# AE612FA0E5597BS0_CM55_HP_View register map
Vendor: Alif Semiconductor; Series: E6; File version: 1.0
CPU: CM55 r1p0, selectable endian, MPU, FPU, double-precision FPU, DSP, VTOR, 8 interrupt priority bits, 1 SAU regions
Registers are 32-bit, read-write, reset 0x0 unless marked. A register's access mark holds for its fields unless they carry their own. Offsets are from the block's base; [hi:lo] are bit positions; {n}, {i} and the like mark numbered series; 'fields as' and 'values as' point back to an identical list.

## NPU_HG
Base 0x49042000
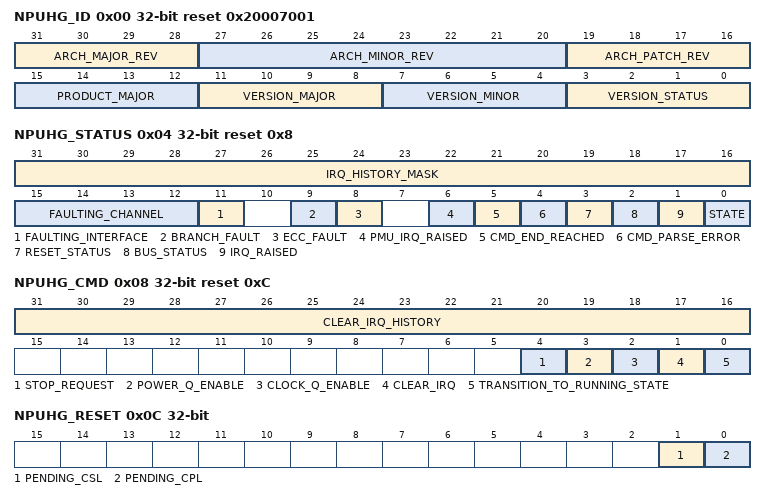
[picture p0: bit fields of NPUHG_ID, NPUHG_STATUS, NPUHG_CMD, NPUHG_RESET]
0x00 NPUHG_ID ro reset 0x20007001 — ID Register
  [31:28] ARCH_MAJOR_REV — This value is the major architecture version number, a in the architecture version a.b
  [27:20] ARCH_MINOR_REV — This value is the minor architecture version number, b in the architecture version a.b
  [19:16] ARCH_PATCH_REV — This value is the patch number of the architecture version a.b
  [15:12] PRODUCT_MAJOR — Product major ID number (unique per base product)
  [11:8] VERSION_MAJOR — This value is the n for the R part of an RnPn release number
  [7:4] VERSION_MINOR — This value is the n for the P part of an RnPn release number
  [3:0] VERSION_STATUS — This value is the version of the product
0x04 NPUHG_STATUS ro reset 0x8 — STATUS Register
  [31:16] IRQ_HISTORY_MASK — The IRQ History mask
  [15:12] FAULTING_CHANNEL — The faulting channel on a bus abort
  [11] FAULTING_INTERFACE — The faulting interface on bus abort
  [9] BRANCH_FAULT
    0=No branch fault; 1=Branch fault detected
  [8] ECC_FAULT
    0=No ECC fault detected; 1=ECC fault detected
  [6] PMU_IRQ_RAISED
    0=No PMU IRQ raised; 1=PMU IRQ raised
  [5] CMD_END_REACHED
    0=Command stream end is not reached; 1=Command stream end is reached
  [4] CMD_PARSE_ERROR
    0=No parsing error; 1=Command stream parsing error detected
  [3] RESET_STATUS
    0=No reset in progress; 1=Reset in progress
  [2] BUS_STATUS
    0=No bus fault; 1=Bus abort detected and processing halted
  [1] IRQ_RAISED
    0=IRQ not raised; 1=IRQ raised
  [0] STATE
    0=NPU is in stopped state; 1=NPU is in running state
0x08 NPUHG_CMD reset 0xC — CMD Register
  [31:16] CLEAR_IRQ_HISTORY — Clears the IRQ history mask
  [4] STOP_REQUEST — Write 1 to this bit to request STOP after completing any already-started commands
  [3] POWER_Q_ENABLE — Write 1 to this bit to enable power off using power q-interface
  [2] CLOCK_Q_ENABLE — Write 1 to this bit to enable clock off using clock q-interface and enable the requester clock gate
  [1] CLEAR_IRQ — Write 1 to clear the IRQ status in the NPUHG_STATUS register. Writing 0 has no effect.
  [0] TRANSITION_TO_RUNNING_STATE — Write 1 to transition the NPU to running state. Writing 0 has no effect.
0x0C NPUHG_RESET — RESET Register
  [1] PENDING_CSL — Current security level
    0=Secure; 1=Non-secure
  [0] PENDING_CPL — Current privilege level
    0=User; 1=Privileged
0x10 NPUHG_QBASE — QBASE Register
  [31:0] OFFSET
0x14 NPUHG_QBASE_HI — QBASE_HI Register
  [7:0] OFFSET
0x18 NPUHG_QREAD ro — QREAD Register
  [31:0] QREAD — The read offset of the current command under execution
0x1C NPUHG_QCONFIG — QCONFIG Register
  [1:0] CMD_REGION0 — The command region configuration number
0x20 NPUHG_QSIZE — QSIZE Register
  [31:0] QSIZE — The size of the next command stream to be executed by the NPU
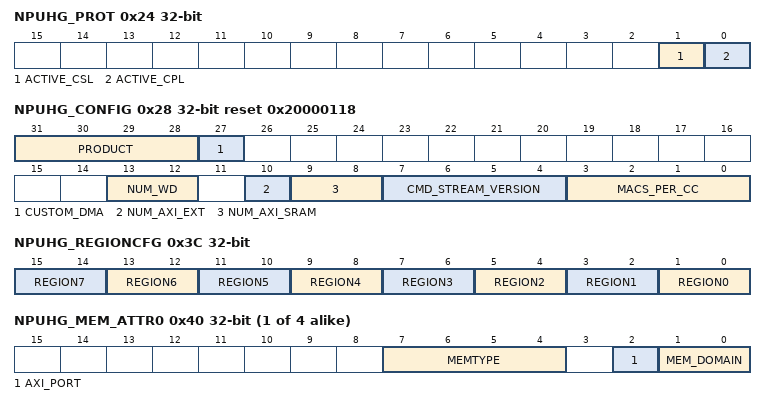
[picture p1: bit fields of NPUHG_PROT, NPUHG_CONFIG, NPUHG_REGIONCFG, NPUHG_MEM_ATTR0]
0x24 NPUHG_PROT ro — PROT Register
  [1] ACTIVE_CSL — The current security level
    0=Secure; 1=Non secure
  [0] ACTIVE_CPL — The current privilege level
    0=User; 1=Privileged
0x28 NPUHG_CONFIG ro reset 0x20000118 — CONFIG Register
  [31:28] PRODUCT — The product configuration
  [27] CUSTOM_DMA — The custom DMA configuration
  [13:12] NUM_WD — The log2 of the number of standard weight decoders
  [10] NUM_AXI_EXT — The log2 of the number of AXI External memory interfaces
  [9:8] NUM_AXI_SRAM — The log2 of the number of AXI SRAM interfaces
  [7:4] CMD_STREAM_VERSION — The command stream version accepted by this NPU
  [3:0] MACS_PER_CC — The log2(MACs/clock cycle)
0x30 NPUHG_COND_STATUS ro — COND_STATUS Register
  [0] RESULT_FLAG — The tensor result flag. For OFM with a single element, this is bit 0 of the value. Otherwise unpredictable.
0x38 NPUHG_POWER_CTRL — POWER_CTRL Register
  [5:0] MAC_STEP_CYCLES — MAC power ramping up/down control
0x3C NPUHG_REGIONCFG — REGIONCFG Register
  [2n+1:2n] REGION{n} (n=0..7) — Bits for Region{n} Configuration
{0x40+4i} NPUHG_MEM_ATTR{i} (i=0..3) — MEM_ATTR{i} Register
  [7:4] MEMTYPE — Memtype to be used to encode AxCACHE signals
  [2] AXI_PORT — AXI port select
  [1:0] MEM_DOMAIN — Memory domain
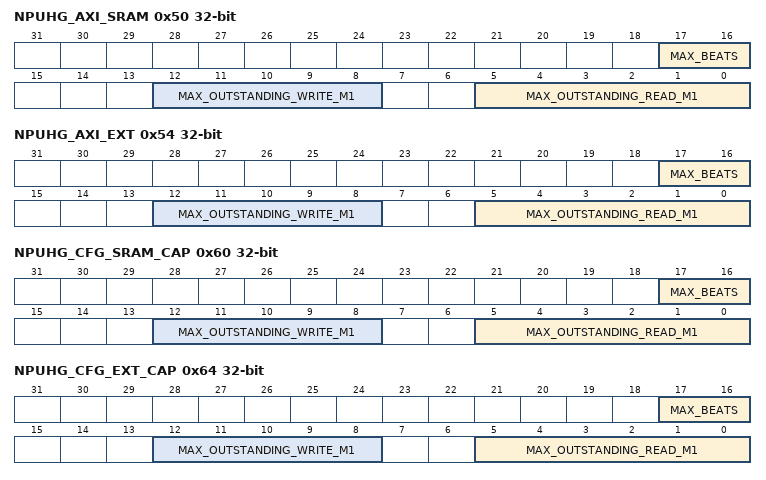
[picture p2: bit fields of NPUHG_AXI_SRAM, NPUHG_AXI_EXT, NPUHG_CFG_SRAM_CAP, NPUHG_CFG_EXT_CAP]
0x50 NPUHG_AXI_SRAM — AXI_SRAM Register
  [17:16] MAX_BEATS — Burst split alignment
  [12:8] MAX_OUTSTANDING_WRITE_M1 — Maximum number of outstanding AXI write transactions per port - 1
  [5:0] MAX_OUTSTANDING_READ_M1 — Maximum number of outstanding AXI read transactions per port - 1
0x54 NPUHG_AXI_EXT — AXI_EXT Register
  fields as NPUHG_AXI_SRAM
0x60 NPUHG_CFG_SRAM_CAP ro — CFG_SRAM_CAP Register
  fields as NPUHG_AXI_SRAM
0x64 NPUHG_CFG_EXT_CAP ro — CFG_EXT_CAP Register
  fields as NPUHG_AXI_SRAM
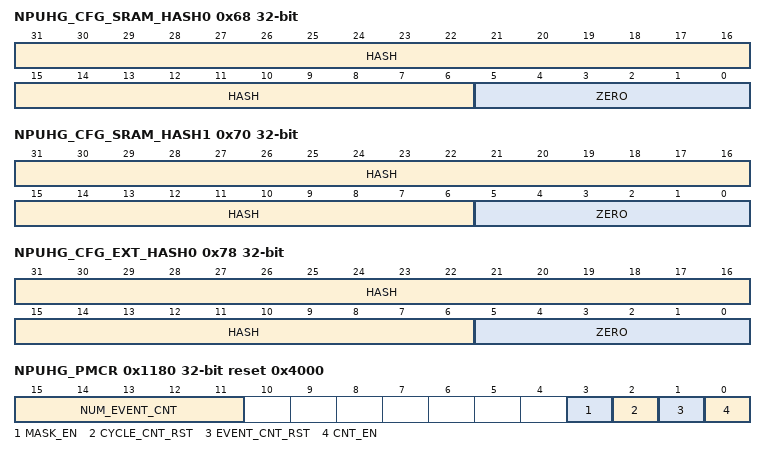
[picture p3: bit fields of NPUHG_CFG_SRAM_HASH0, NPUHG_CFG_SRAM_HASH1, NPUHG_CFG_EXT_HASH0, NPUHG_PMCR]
0x68 NPUHG_CFG_SRAM_HASH0 ro — CFG_SRAM_HASH0 Register
  [31:6] HASH — Hash function
  [5:0] ZERO — Must be zero
0x6C NPUHG_CFG_SRAM_HASH0_HI ro — CFG_SRAM_HASH0_HI Register
  [7:0] HASH — Hash function
0x70 NPUHG_CFG_SRAM_HASH1 ro — CFG_SRAM_HASH1 Register
  [31:6] HASH — Hash function
  [5:0] ZERO — Must be zero
0x74 NPUHG_CFG_SRAM_HASH1_HI ro — CFG_SRAM_HASH1_HI Register
  [7:0] HASH — Hash function
0x78 NPUHG_CFG_EXT_HASH0 ro — CFG_EXT_HASH0 Register
  [31:6] HASH — Hash function
  [5:0] ZERO — Must be zero
0x7C NPUHG_CFG_EXT_HASH0_HI ro — CFG_EXT_HASH0_HI Register
  [7:0] HASH — Hash function
{0x80+8i} NPUHG_BASEP{i} (i=0..7) — BASEP{i} Register
  [31:0] OFFSET
{0x84+8i} NPUHG_BASEP{i}_HI (i=0..7) — BASEP{i}_HI Register
  [7:0] OFFSET
0xFD0 NPUHG_PID4 ro reset 0x4 — PID4 Register
  [31:0] PID4 — Byte 4 of Peripheral NPUHG_ID (Lower 8 bits valid)
{0xFC0+4i} NPUHG_PID{i} ro (i=5..7) — PID{i} Register
  [31:0] PID{i} — Byte {i} of Peripheral NPUHG_ID (Lower 8 bits valid)
0xFE0 NPUHG_PID0 ro reset 0x82 — PID0 Register
  [31:0] PID0 — Byte 0 of Peripheral NPUHG_ID (Lower 8 bits valid)
0xFE4 NPUHG_PID1 ro reset 0xB5 — PID1 Register
  [31:0] PID1 — Byte 1 of Peripheral NPUHG_ID (Lower 8 bits valid)
0xFE8 NPUHG_PID2 ro reset 0xB — PID2 Register
  [31:0] PID2 — Byte 2 of Peripheral NPUHG_ID (Lower 8 bits valid)
0xFEC NPUHG_PID3 ro — PID3 Register
  [31:0] PID3 — Byte 1 of Peripheral NPUHG_ID (Lower 8 bits valid)
0xFF0 NPUHG_CID0 ro reset 0xD — CID0 Register
  [31:0] CID0 — Byte 0 of Component NPUHG_ID (Lower 8 bits valid)
0xFF4 NPUHG_CID1 ro reset 0xF0 — CID1 Register
  [31:0] CID1 — Byte 1 of Component NPUHG_ID (Lower 8 bits valid)
0xFF8 NPUHG_CID2 ro reset 0x5 — CID2 Register
  [31:0] CID2 — Byte 2 of Component NPUHG_ID (Lower 8 bits valid)
0xFFC NPUHG_CID3 ro reset 0xB1 — CID3 Register
  [31:0] CID3 — Byte 3 of Component NPUHG_ID (Lower 8 bits valid)
0x1180 NPUHG_PMCR reset 0x4000 — PMCR Register
  [15:11] NUM_EVENT_CNT — Number of event counters
  [3] MASK_EN — PMU can be enabled/disabled by command stream operation NPU_OP_PMU_MASK
  [2] CYCLE_CNT_RST — Reset cycle counter
  [1] EVENT_CNT_RST — Reset event counter
  [0] CNT_EN — Enable counter
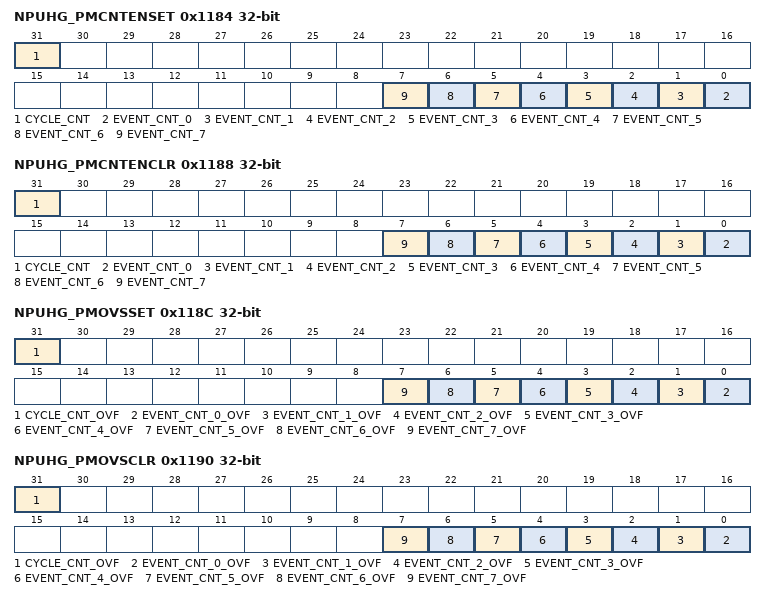
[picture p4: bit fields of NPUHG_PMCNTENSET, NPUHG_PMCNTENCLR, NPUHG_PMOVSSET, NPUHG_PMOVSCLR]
0x1184 NPUHG_PMCNTENSET — PMCNTENSET Register
  [31] CYCLE_CNT — NPUHG_PMCCNTR enable bit
  [n] EVENT_CNT_{n} (n=0..7) — Event counter enable bit for NPUHG_PMEVCNTR{n}
0x1188 NPUHG_PMCNTENCLR — PMCNTENCLR Register
  [31] CYCLE_CNT — NPUHG_PMCCNTR disable bit
  [n] EVENT_CNT_{n} (n=0..7) — Event counter disable bit for NPUHG_PMEVCNTR{n}
0x118C NPUHG_PMOVSSET — PMOVSSET Register
  [31] CYCLE_CNT_OVF — NPUHG_PMCCNTR overflow set bit
  [n] EVENT_CNT_{n}_OVF (n=0..7) — Event counter overflow set bit for NPUHG_PMEVCNTR{n}
0x1190 NPUHG_PMOVSCLR — PMOVSCLR Register
  [31] CYCLE_CNT_OVF — NPUHG_PMCCNTR overflow clear bit
  [n] EVENT_CNT_{n}_OVF (n=0..7) — Event counter overflow clear bit for NPUHG_PMEVCNTR{n}
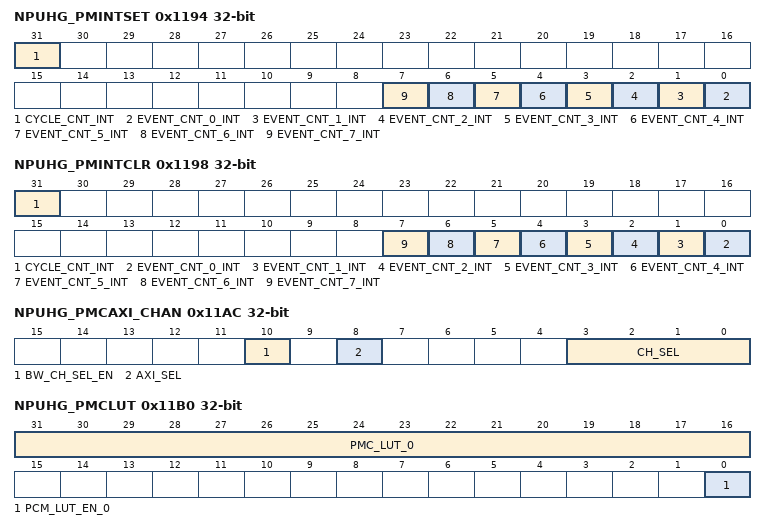
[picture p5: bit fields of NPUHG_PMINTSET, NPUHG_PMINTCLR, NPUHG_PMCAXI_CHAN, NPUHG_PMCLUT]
0x1194 NPUHG_PMINTSET — PMINTSET Register
  [31] CYCLE_CNT_INT — NPUHG_PMCCNTR overflow interrupt request enable bit
  [n] EVENT_CNT_{n}_INT (n=0..7) — Event counter overflow interrupt request enable bit for NPUHG_PMEVCNTR{n}
0x1198 NPUHG_PMINTCLR — PMINTCLR Register
  [31] CYCLE_CNT_INT — NPUHG_PMCCNTR overflow interrupt request disable bit
  [n] EVENT_CNT_{n}_INT (n=0..7) — Event counter overflow interrupt request disable bit for NPUHG_PMEVCNTR{n}
0x11A0 NPUHG_PMCCNTR — PMCCNTR Register
  [31:0] CYCLE_CNT — Cycle count
0x11A4 NPUHG_PMCCNTR_HI — PMCCNTR_HI Register
  [15:0] CYCLE_CNT — Cycle count
0x11AC NPUHG_PMCAXI_CHAN — PMCAXI_CHAN Register
  [10] BW_CH_SEL_EN — Bandwidth channel selector
  [8] AXI_SEL — AXI port select for latency measurements
  [3:0] CH_SEL — Channel select for latency measurements
0x11B0 NPUHG_PMCLUT — PMCLUT Register
  [31:16] PMC_LUT_0 — PMU lookup table for event counter 0
  [0] PCM_LUT_EN_0 — PMU lookup table enable for event counter 0
{0x1300+4i} NPUHG_PMEVCNTR{i} (i=0..7) — PMEVCNTR{i} Register
  [31:0] COUNT — Count word
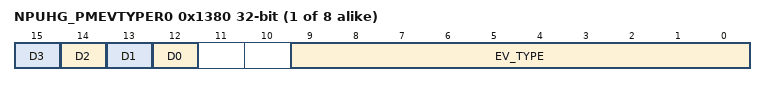
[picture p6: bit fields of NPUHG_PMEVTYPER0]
{0x1380+4i} NPUHG_PMEVTYPER{i} (i=0..7) — PMEVTYPER{i} Register
  [n+12] D{n} (n=0..3) — Counting disabled for AXI port {n}
  [9:0] EV_TYPE — Event Type
